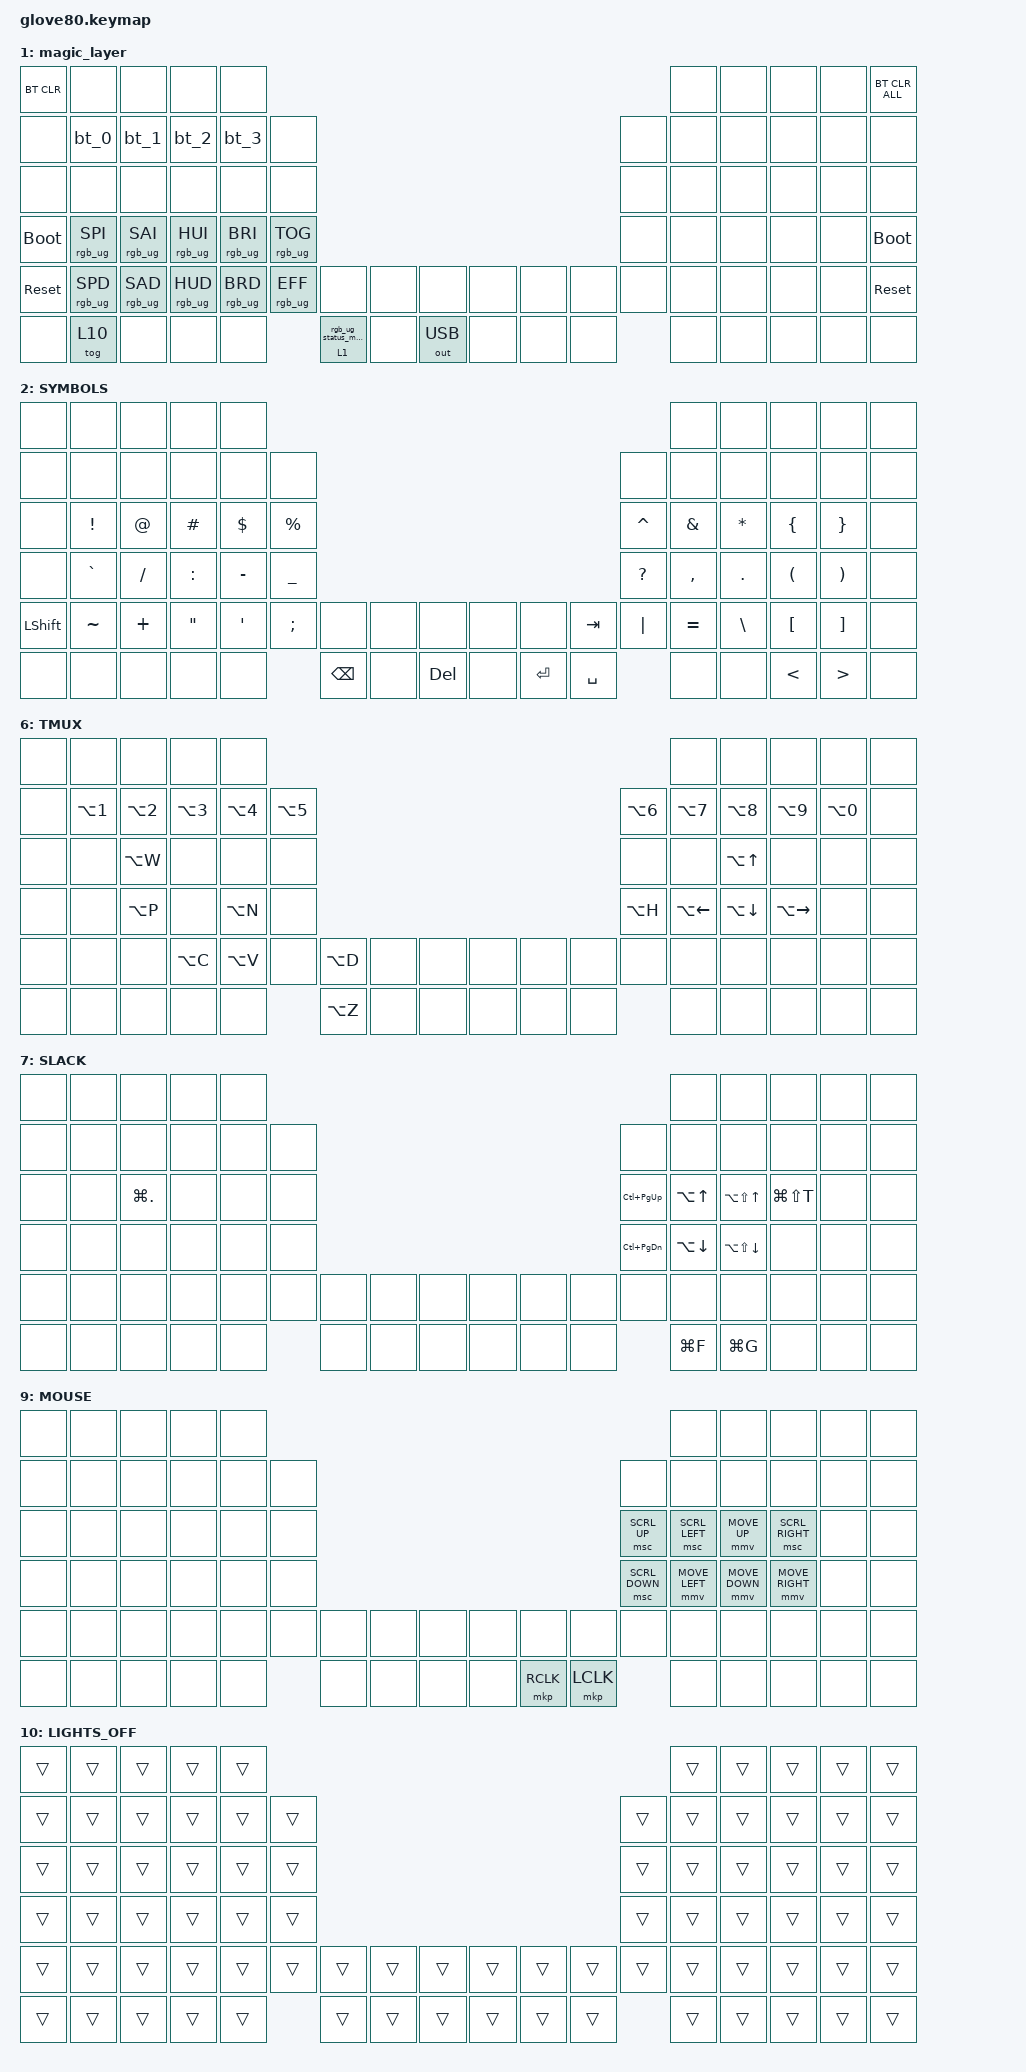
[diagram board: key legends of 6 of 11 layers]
/*
 * Copyright (c) 2020 The ZMK Contributors
 *
 * SPDX-License-Identifier: MIT
 */

#define ZMK_POINTING_DEFAULT_MOVE_VAL 1000  // Override cursor speed, default: 600
#define ZMK_POINTING_DEFAULT_SCRL_VAL 20    // Override scroll speed, default: 10

#include <behaviors.dtsi>
#include <dt-bindings/zmk/bt.h>
#include <dt-bindings/zmk/keys.h>
#include <dt-bindings/zmk/outputs.h>
#include <dt-bindings/zmk/pointing.h>
#include <dt-bindings/zmk/rgb.h>

#define HYPER LC(LS(LG(LALT)))

// layers

#define DEFAULT 0
#define LOWER 1
#define MAGIC 2
#define FACTORY_TEST 3

&lt {
    quick-tap-ms = <175>;
    hold-trigger-on-release;
};

/ {
    behaviors {
        // For the "layer" key, it'd nice to be able to use it as either a shift or a toggle.
        // Configure it as a tap dance, so the first tap (or hold) is a &mo and the second tap is a &to

        layer_td: tap_dance_0 {
            compatible = "zmk,behavior-tap-dance";
            label = "LAYER_TAP_DANCE";
            #binding-cells = <0>;
            tapping-term-ms = <200>;
            bindings = <&mo 0>, <&to 0>;
        };

        magic: magic_hold_tap {
            compatible = "zmk,behavior-hold-tap";
            label = "MAGIC_HOLD_TAP";
            #binding-cells = <2>;
            flavor = "tap-preferred";
            tapping-term-ms = <200>;
            bindings = <&mo>, <&rgb_ug_status_macro>;
        };
    };

    macros {
        rgb_ug_status_macro: rgb_ug_status_macro_0 {
            label = "RGB_UG_STATUS";
            compatible = "zmk,behavior-macro";
            #binding-cells = <0>;
            bindings = <&rgb_ug RGB_STATUS>;
        };

        bt_0: bt_profile_macro_0 {
            label = "BT_0";
            compatible = "zmk,behavior-macro";
            #binding-cells = <0>;
            bindings = <&out OUT_BLE &bt BT_SEL 0>;
        };

        bt_1: bt_profile_macro_1 {
            label = "BT_1";
            compatible = "zmk,behavior-macro";
            #binding-cells = <0>;
            bindings = <&out OUT_BLE &bt BT_SEL 1>;
        };

        bt_2: bt_profile_macro_2 {
            label = "BT_2";
            compatible = "zmk,behavior-macro";
            #binding-cells = <0>;
            bindings = <&out OUT_BLE &bt BT_SEL 2>;
        };

        bt_3: bt_profile_macro_3 {
            label = "BT_3";
            compatible = "zmk,behavior-macro";
            #binding-cells = <0>;
            bindings = <&out OUT_BLE &bt BT_SEL 3>;
        };
    };

    // layer_indicators in rgb-layer-indicator.patch sets each layer's lit key and colour by its
    // position here: update that table if layers are added or reordered.

    keymap {
        compatible = "zmk,keymap";

        default_layer {
            // ---------------------------------------------------------------------------------------------------------------------------------
            // |  F1   |  F2 |  F3 |  F4  |  F5  |                                                               |  F6   |  F7   |  F8  |   F9  |  F10 |
            // |  =    |  1  |  2  |  3   |  4   |  5   |                                                 |  6   |   7   |   8   |  9   |   0   |   -  |
            // |  TAB  |  Q  |  W  |  E   |  R   |  T   |                                                 |  Y   |   U   |   I   |  O   |   P   |   \  |
            // |  ESC  |  A  |  S  |  D   |  F   |  G   |                                                 |  H   |   J   |   K   |  L   |   ;   |   '  |
            // |   `   |  Z  |  X  |  C   |  V   |  B   | LSHFT | LCTRL | LOWER | | LGUI  | RCTRL | RSHFT |  N   |   M   |   ,   |  .   |   /   | PGUP |
            // | MAGIC | HOME| END | LEFT | RIGHT|      | BSPC  | DEL   | LALT  | | RALT  | RET   | SPACE |      |  UP   | DOWN  |  [   |   ]   | PGDN |

            bindings = <
&lt 8 F1        &lt 7 F2   &kp F3     &kp F4     &kp F5                                                                                                                             &kp F6     &kp F7     &kp F8    &kp F9    &kp F10
&kp EQUAL       &kp N1     &kp N2     &kp N3     &kp N4     &kp N5                                                                                                          &kp N6  &kp N7     &kp N8     &kp N9    &kp N0    &kp LC(LG(Q))
&kp TAB         &kp Q      &kp W      &kp E      &kp R      &kp T                                                                                                           &kp Y   &kp U      &kp I      &kp O     &kp P     &kp BSLH
&kp GRAVE       &kp A      &kp S      &kp D      &kp F      &kp G                                                                                                           &kp H   &kp J      &kp K      &kp L     &kp SEMI  &kp SQT
&kp LEFT_SHIFT  &kp Z      &kp X      &kp C      &kp V      &kp B   &lt (4) LA(LC(LEFT_GUI))  &lt (5) LC(ESCAPE)  &lt (9) LC(C)  &kp LEFT_ALT  &kp RCTRL  &mt LEFT_GUI TAB  &kp N   &kp M      &kp COMMA  &kp DOT   &kp FSLH  &kp MINUS
&lt 1 GLOBE     &kp LG(Z)  &kp LG(X)  &kp LG(C)  &kp LG(V)          &kp BSPC                  &mo 2               &kp DELETE     &mo 6         &kp RET    &lt 3 SPACE               &kp LG(F)  &none      &kp LBKT  &kp RBKT  &mo 1
            >;
        };

        magic_layer {
            bindings = <
&bt BT_CLR   &none            &none            &none            &none                                                                                          &none  &none  &none  &none  &bt BT_CLR_ALL
&none        &bt_0            &bt_1            &bt_2            &bt_3            &none                                                                  &none  &none  &none  &none  &none  &none
&none        &none            &none            &none            &none            &none                                                                  &none  &none  &none  &none  &none  &none
&bootloader  &rgb_ug RGB_SPI  &rgb_ug RGB_SAI  &rgb_ug RGB_HUI  &rgb_ug RGB_BRI  &rgb_ug RGB_TOG                                                        &none  &none  &none  &none  &none  &bootloader
&sys_reset   &rgb_ug RGB_SPD  &rgb_ug RGB_SAD  &rgb_ug RGB_HUD  &rgb_ug RGB_BRD  &rgb_ug RGB_EFF  &none       &none  &none         &none  &none  &none  &none  &none  &none  &none  &none  &sys_reset
&none        &tog 10          &none            &none            &none                             &magic 1 0  &none  &out OUT_USB  &none  &none  &none         &none  &none  &none  &none  &none
            >;
        };

        SYMBOLS {
            bindings = <
&none           &none      &none      &none              &none                                                                                                         &none          &none          &none                 &none                  &none
&none           &none      &none      &none              &none             &none                                                                         &none         &none          &none          &none                 &none                  &none
&none           &kp EXCL   &kp AT     &kp POUND          &kp DOLLAR        &kp PERCENT                                                                   &kp CARET     &kp AMPERSAND  &kp STAR       &kp LEFT_BRACE        &kp RIGHT_BRACE        &none
&none           &kp GRAVE  &kp SLASH  &kp COLON          &kp MINUS         &kp UNDER                                                                     &kp QUESTION  &kp COMMA      &kp PERIOD     &kp LEFT_PARENTHESIS  &kp RIGHT_PARENTHESIS  &none
&kp LEFT_SHIFT  &kp TILDE  &kp PLUS   &kp DOUBLE_QUOTES  &kp SINGLE_QUOTE  &kp SEMICOLON  &none          &none  &none       &none  &none      &kp TAB    &kp PIPE      &kp EQUAL      &kp BACKSLASH  &kp LBKT              &kp RBKT               &none
&none           &none      &none      &none              &none                            &kp BACKSPACE  &none  &kp DELETE  &none  &kp ENTER  &kp SPACE                &none          &none          &kp LESS_THAN         &kp GREATER_THAN       &none
            >;
        };

        ARROWS_LAYER {
            bindings = <
&none           &none       &none            &none          &none                                                                                                                       &none     &none     &none      &none      &none
&none           &none       &none            &none          &none        &none                                                                                                   &none  &none     &none     &none      &none      &none
&none           &none       &kp LG(W)        &none          &none        &none                                                                                                   &none  &kp HOME  &kp UP    &kp END    &kp PG_UP  &none
&none           &kp LG(N1)  &kp LC(LS(TAB))  &kp LG(GRAVE)  &kp LC(TAB)  &kp LG(N9)                                                                                              &none  &kp LEFT  &kp DOWN  &kp RIGHT  &kp PG_DN  &none
&kp LEFT_SHIFT  &none       &none            &none          &none        &none       &kp LS(LA(LG(LEFT)))  &kp LS(LA(LG(RIGHT)))  &kp LS(LA(LG(UP_ARROW)))  &none  &none  &none  &none  &none     &none     &none      &none      &none
&none           &none       &none            &none          &none                    &none                 &none                  &kp LS(LA(LG(DOWN)))      &none  &none  &none         &none     &none     &none      &none      &none
            >;
        };

        LAUNCHER {
            bindings = <
&none  &none                   &none                   &none                   &none                                                                                                             &none                   &none                   &none                   &none                   &none
&none  &kp RS(RA(RC(RG(N1))))  &kp RS(RA(RC(RG(N2))))  &kp RS(RA(RC(RG(N3))))  &kp RS(RA(RC(RG(N4))))  &kp RC(RS(RA(RG(N5))))                                            &kp RS(RA(RC(RG(N6))))  &kp RS(RA(RC(RG(N7))))  &kp RS(RA(RC(RG(N8))))  &kp RS(RA(RC(RG(N9))))  &kp RS(RA(RC(RG(N0))))  &none
&none  &kp RS(RA(RC(RG(Q))))   &kp RS(RG(RA(RC(W))))   &kp RS(RA(RC(RG(E))))   &kp RS(RC(RG(RA(R))))   &kp RS(RC(RA(RG(T))))                                             &kp RS(RA(RC(RG(Y))))   &kp RS(RA(RC(RG(U))))   &kp RS(RA(RC(RG(I))))   &kp RS(RA(RC(RG(O))))   &kp RS(RA(RC(RG(P))))   &none
&none  &kp RS(RA(RC(RG(A))))   &kp RS(RA(RC(RG(S))))   &kp RS(RA(RC(RG(D))))   &kp RS(RA(RC(RG(F))))   &kp RS(RA(RC(RG(G))))                                             &kp RS(RA(RC(RG(H))))   &kp RS(RA(RC(RG(J))))   &kp RA(RS(RC(RG(K))))   &kp RS(RC(RG(RA(L))))   &none                   &none
&none  &kp RS(RA(RC(RG(Z))))   &kp RS(RA(RC(RG(X))))   &kp RS(RA(RC(RG(C))))   &kp RS(RA(RC(RG(V))))   &kp RS(RA(RC(RG(B))))   &none  &none  &none  &none  &none  &none  &kp RS(RA(RC(RG(N))))   &kp RS(RA(RC(RG(M))))   &none                   &none                   &none                   &none
&none  &none                   &none                   &none                   &none                                           &none  &none  &none  &none  &none  &none                          &none                   &none                   &none                   &none                   &none
            >;
        };

        LAUNCHER_PREFILL {
            bindings = <
&none  &none                   &none                   &none                   &none                                                                                                             &none                   &none                   &none                   &none                   &none
&none  &kp RS(RA(RC(LG(N1))))  &kp RS(RA(RC(LG(N2))))  &kp RS(RA(RC(LG(N3))))  &kp RS(RA(RC(RG(N4))))  &kp RC(RS(RA(LG(N5))))                                            &kp RS(RA(RC(LG(N6))))  &kp RS(RA(RC(LG(N7))))  &kp RS(RA(RC(LG(N8))))  &kp RS(RA(RC(LG(N9))))  &kp RS(RA(RC(LG(N0))))  &none
&none  &kp RS(RA(RC(LG(Q))))   &kp RS(RA(RC(LG(W))))   &kp RS(RA(RC(LG(E))))   &kp RS(RC(RA(LG(R))))   &kp RS(RC(RA(LG(T))))                                             &kp RS(RA(RC(LG(Y))))   &kp RS(RA(RC(LG(U))))   &kp RS(RA(RC(LG(I))))   &kp RS(RA(RC(LG(O))))   &kp RS(RA(RC(LG(P))))   &none
&none  &kp RS(RA(RC(LG(A))))   &kp RS(RA(RC(LG(S))))   &kp RS(RA(RC(LG(D))))   &kp RS(RA(RC(LG(F))))   &kp RS(RA(RC(LG(G))))                                             &kp RS(RA(RC(LG(H))))   &kp RS(RA(RC(LG(J))))   &kp RA(RS(RC(LG(K))))   &kp RS(RC(RA(LG(L))))   &none                   &none
&none  &kp RS(RA(RC(LG(Z))))   &kp RS(RA(RC(LG(X))))   &kp RS(RA(RC(LG(C))))   &kp RS(RA(RC(LG(V))))   &kp RS(RA(RC(LG(B))))   &none  &none  &none  &none  &none  &none  &kp RS(RA(RC(LG(N))))   &kp RS(RA(RC(LG(M))))   &none                   &none                   &none                   &none
&none  &none                   &none                   &none                   &none                                           &none  &none  &none  &none  &none  &none                          &none                   &none                   &none                   &none                   &none
            >;
        };

        TMUX {
            bindings = <
&none  &none       &none       &none       &none                                                                             &none         &none         &none          &none       &none
&none  &kp LA(N1)  &kp LA(N2)  &kp LA(N3)  &kp LA(N4)  &kp LA(N5)                                                &kp LA(N6)  &kp LA(N7)    &kp LA(N8)    &kp LA(N9)     &kp LA(N0)  &none
&none  &none       &kp LA(W)   &none       &none       &none                                                     &none       &none         &kp LA(UP)    &none          &none       &none
&none  &none       &kp LA(P)   &none       &kp LA(N)   &none                                                     &kp LA(H)   &kp LA(LEFT)  &kp LA(DOWN)  &kp LA(RIGHT)  &none       &none
&none  &none       &none       &kp LA(C)   &kp LA(V)   &none       &kp LA(D)  &none  &none  &none  &none  &none  &none       &none         &none         &none          &none       &none
&none  &none       &none       &none       &none                   &kp LA(Z)  &none  &none  &none  &none  &none              &none         &none         &none          &none       &none
            >;
        };

        SLACK {
            bindings = <
&none  &none  &none           &none  &none                                                                      &none         &none             &none          &none  &none
&none  &none  &none           &none  &none  &none                                            &none              &none         &none             &none          &none  &none
&none  &none  &kp LG(PERIOD)  &none  &none  &none                                            &kp LC(PAGE_UP)    &kp LA(UP)    &kp LA(LS(UP))    &kp LG(LS(T))  &none  &none
&none  &none  &none           &none  &none  &none                                            &kp LC(PAGE_DOWN)  &kp LA(DOWN)  &kp LA(LS(DOWN))  &none          &none  &none
&none  &none  &none           &none  &none  &none  &none  &none  &none  &none  &none  &none  &none              &none         &none             &none          &none  &none
&none  &none  &none           &none  &none         &none  &none  &none  &none  &none  &none                     &kp LG(F)     &kp LG(G)         &none          &none  &none
            >;
        };

        MEDIA {
            bindings = <
&none  &none  &none  &none  &none                                                                                                                  &none  &none  &none  &none  &none
&none  &none  &none  &none  &none  &none                                                                                    &none                  &none  &none  &none  &none  &none
&none  &none  &none  &none  &none  &none                                                                                    &none                  &none  &none  &none  &none  &none
&none  &none  &none  &none  &none  &none                                                                                    &kp RS(RA(RG(LC(H))))  &none  &none  &none  &none  &none
&none  &none  &none  &none  &none  &none  &none  &none  &none  &kp C_VOLUME_UP    &kp RA(RS(RG(LC(U))))  &kp LG(LS(SPACE))  &none                  &none  &none  &none  &none  &none
&none  &none  &none  &none  &none         &none  &none  &none  &kp C_VOLUME_DOWN  &kp RS(RA(RG(LC(M))))  &none                                     &none  &none  &none  &none  &none
            >;
        };

        MOUSE {
            bindings = <
&none  &none  &none  &none  &none                                                                           &none           &none           &none            &none  &none
&none  &none  &none  &none  &none  &none                                                    &none           &none           &none           &none            &none  &none
&none  &none  &none  &none  &none  &none                                                    &msc SCRL_UP    &msc SCRL_LEFT  &mmv MOVE_UP    &msc SCRL_RIGHT  &none  &none
&none  &none  &none  &none  &none  &none                                                    &msc SCRL_DOWN  &mmv MOVE_LEFT  &mmv MOVE_DOWN  &mmv MOVE_RIGHT  &none  &none
&none  &none  &none  &none  &none  &none  &none  &none  &none  &none  &none      &none      &none           &none           &none           &none            &none  &none
&none  &none  &none  &none  &none         &none  &none  &none  &none  &mkp RCLK  &mkp LCLK                  &none           &none           &none            &none  &none
            >;
        };

        // Not a real layer: an on/off switch for the per-layer key lights, toggled by the HOME
        // position on magic_layer. Its position (10) is hardcoded in rgb-layer-indicator.patch.

        LIGHTS_OFF {
            bindings = <
&trans  &trans  &trans  &trans  &trans                                                                  &trans  &trans  &trans  &trans  &trans
&trans  &trans  &trans  &trans  &trans  &trans                                                  &trans  &trans  &trans  &trans  &trans  &trans
&trans  &trans  &trans  &trans  &trans  &trans                                                  &trans  &trans  &trans  &trans  &trans  &trans
&trans  &trans  &trans  &trans  &trans  &trans                                                  &trans  &trans  &trans  &trans  &trans  &trans
&trans  &trans  &trans  &trans  &trans  &trans  &trans  &trans  &trans  &trans  &trans  &trans  &trans  &trans  &trans  &trans  &trans  &trans
&trans  &trans  &trans  &trans  &trans          &trans  &trans  &trans  &trans  &trans  &trans          &trans  &trans  &trans  &trans  &trans
            >;
        };
    };
};
